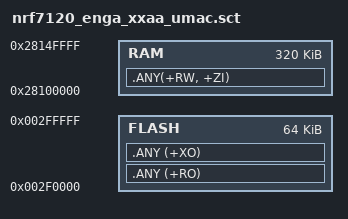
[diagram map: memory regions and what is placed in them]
LOAD 0x002F0000 0x00010000
{
    FLASH 0x002F0000 0x00010000
    {
    
        .ANY (+RO)
        .ANY (+XO)
    }

    RAM 0x28100000 0x00050000
    {
    .ANY(+RW, +ZI) ; RW data and ZI data
    }

}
